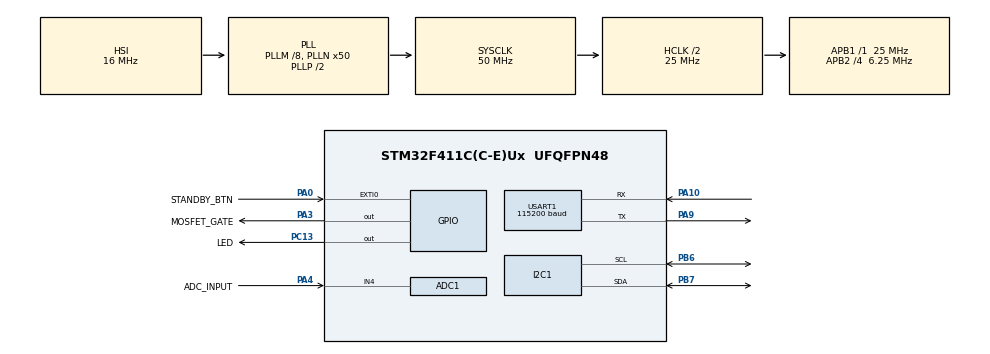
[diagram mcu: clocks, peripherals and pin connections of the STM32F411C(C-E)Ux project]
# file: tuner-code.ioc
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ADC1.Channel-0\#ChannelRegularConversion=ADC_CHANNEL_4
ADC1.ClockPrescaler=ADC_CLOCK_SYNC_PCLK_DIV8
ADC1.ContinuousConvMode=ENABLE
ADC1.DMAContinuousRequests=ENABLE
ADC1.NbrOfConversionFlag=1
ADC1.Rank-0\#ChannelRegularConversion=1
ADC1.SamplingTime-0\#ChannelRegularConversion=ADC_SAMPLETIME_84CYCLES
ADC1.master=1
Dma.ADC1.0.Direction=DMA_PERIPH_TO_MEMORY
Dma.ADC1.0.FIFOMode=DMA_FIFOMODE_DISABLE
Dma.ADC1.0.Instance=DMA2_Stream0
Dma.ADC1.0.MemDataAlignment=DMA_MDATAALIGN_HALFWORD
Dma.ADC1.0.MemInc=DMA_MINC_ENABLE
Dma.ADC1.0.Mode=DMA_NORMAL
Dma.ADC1.0.PeriphDataAlignment=DMA_PDATAALIGN_HALFWORD
Dma.ADC1.0.PeriphInc=DMA_PINC_DISABLE
Dma.ADC1.0.Priority=DMA_PRIORITY_HIGH
Dma.I2C1_TX.2.Direction=DMA_MEMORY_TO_PERIPH
Dma.I2C1_TX.2.FIFOMode=DMA_FIFOMODE_DISABLE
Dma.I2C1_TX.2.Instance=DMA1_Stream1
Dma.I2C1_TX.2.MemDataAlignment=DMA_MDATAALIGN_BYTE
Dma.I2C1_TX.2.MemInc=DMA_MINC_ENABLE
Dma.I2C1_TX.2.Mode=DMA_NORMAL
Dma.I2C1_TX.2.PeriphDataAlignment=DMA_PDATAALIGN_BYTE
Dma.I2C1_TX.2.PeriphInc=DMA_PINC_DISABLE
Dma.I2C1_TX.2.Priority=DMA_PRIORITY_MEDIUM
Dma.Request0=ADC1
Dma.Request1=USART1_TX
Dma.Request2=I2C1_TX
Dma.USART1_TX.1.Direction=DMA_MEMORY_TO_PERIPH
Dma.USART1_TX.1.FIFOMode=DMA_FIFOMODE_DISABLE
Dma.USART1_TX.1.Instance=DMA2_Stream7
Dma.USART1_TX.1.MemDataAlignment=DMA_MDATAALIGN_BYTE
Dma.USART1_TX.1.MemInc=DMA_MINC_ENABLE
Dma.USART1_TX.1.Mode=DMA_NORMAL
Dma.USART1_TX.1.PeriphDataAlignment=DMA_PDATAALIGN_BYTE
Dma.USART1_TX.1.PeriphInc=DMA_PINC_DISABLE
Dma.USART1_TX.1.Priority=DMA_PRIORITY_LOW
I2C1.I2C_Mode=I2C_Fast
Mcu.Family=STM32F4
Mcu.Name=STM32F411C(C-E)Ux
Mcu.Package=UFQFPN48
NVIC.DMA1_Stream1_IRQn=true\:0\:0\:false\:false\:true\:false\:true\:true
NVIC.DMA2_Stream0_IRQn=true\:0\:0\:false\:false\:true\:false\:true\:true
NVIC.DMA2_Stream7_IRQn=true\:0\:0\:false\:false\:true\:false\:true\:true
NVIC.EXTI0_IRQn=true\:0\:0\:false\:false\:true\:true\:true\:true
NVIC.I2C1_EV_IRQn=true\:0\:0\:false\:false\:true\:true\:true\:true
NVIC.PriorityGroup=NVIC_PRIORITYGROUP_4
NVIC.USART1_IRQn=true\:0\:0\:false\:false\:true\:true\:true\:true
PA0-WKUP.GPIO_Label=STANDBY_BTN
PA0-WKUP.Signal=GPXTI0
PA10.Mode=Asynchronous
PA10.Signal=USART1_RX
PA13.Mode=Serial_Wire
PA13.Signal=SYS_JTMS-SWDIO
PA14.Mode=Serial_Wire
PA14.Signal=SYS_JTCK-SWCLK
PA3.GPIO_Label=MOSFET_GATE
PA3.Signal=GPIO_Output
PA4.GPIO_Label=ADC_INPUT
PA4.Signal=ADCx_IN4
PA9.Mode=Asynchronous
PA9.Signal=USART1_TX
PB6.Mode=I2C
PB6.Signal=I2C1_SCL
PB7.Mode=I2C
PB7.Signal=I2C1_SDA
PC13-ANTI_TAMP.GPIO_Label=LED
PC13-ANTI_TAMP.GPIO_ModeDefaultOutputPP=GPIO_MODE_OUTPUT_PP
PC13-ANTI_TAMP.GPIO_PuPd=GPIO_NOPULL
PC13-ANTI_TAMP.PinState=GPIO_PIN_SET
PC13-ANTI_TAMP.Signal=GPIO_Output
ProjectManager.HeapSize=0x200
ProjectManager.StackSize=0x400
ProjectManager.TargetToolchain=CMake
RCC.48MHZClocksFreq_Value=25000000
RCC.AHBCLKDivider=RCC_SYSCLK_DIV2
RCC.AHBFreq_Value=25000000
RCC.APB1Freq_Value=25000000
RCC.APB1TimFreq_Value=25000000
RCC.APB2CLKDivider=RCC_HCLK_DIV4
RCC.APB2Freq_Value=6250000
RCC.APB2TimFreq_Value=12500000
RCC.CortexFreq_Value=25000000
RCC.HCLKFreq_Value=25000000
RCC.HSE_VALUE=25000000
RCC.HSI_VALUE=16000000
RCC.LSE_VALUE=32768
RCC.PLLM=8
RCC.PLLN=50
RCC.SYSCLKFreq_VALUE=50000000
RCC.SYSCLKSource=RCC_SYSCLKSOURCE_PLLCLK
RCC.VCOOutputFreq_Value=100000000
SH.ADCx_IN4.0=ADC1_IN4,IN4
STMicroelectronics.X-CUBE-ALGOBUILD.1.4.0.LibraryCcDSPOoLibraryJjDSPOoLibrary=true
USART1.BaudRate=115200
USART1.Mode=MODE_TX_RX
USART1.VirtualMode=VM_ASYNC
VP_STMicroelectronics.X-CUBE-ALGOBUILD_VS_DSPOoLibraryJjLibrary_1.4.0_1.4.0.Mode=DSPOoLibraryJjLibrary
board=custom

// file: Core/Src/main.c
/* USER CODE BEGIN Header */
/**
  ******************************************************************************
  * @file           : main.c
  * @brief          : Main program body
  ******************************************************************************
  * @attention
  *
  * Copyright (c) 2025 STMicroelectronics.
  * All rights reserved.
  *
  * This software is licensed under terms that can be found in the LICENSE file
  * in the root directory of this software component.
  * If no LICENSE file comes with this software, it is provided AS-IS.
  *
  ******************************************************************************
  */
/* USER CODE END Header */
#include "main.h"

ADC_HandleTypeDef hadc1;
DMA_HandleTypeDef hdma_adc1;

I2C_HandleTypeDef hi2c1;
DMA_HandleTypeDef hdma_i2c1_tx;

UART_HandleTypeDef huart1;
DMA_HandleTypeDef hdma_usart1_tx;

void SystemClock_Config(void);
static void MX_GPIO_Init(void);
static void MX_DMA_Init(void);
static void MX_ADC1_Init(void);
static void MX_I2C1_Init(void);
static void MX_USART1_UART_Init(void);
/* USER CODE BEGIN PFP */
__inline void SystemClockConfig(void)
{
    SystemClock_Config();
}

__inline void MxGpioInit(void)
{
    MX_GPIO_Init();
}

__inline void MxAdcInit(void)
{
    MX_ADC1_Init();
}

__inline void MxDmaInit(void)
{
    MX_DMA_Init();
}

__inline void MxUartInit(void)
{
    MX_USART1_UART_Init();
}

__inline void MxI2cInit(void)
{
  MX_I2C1_Init();
}
/* USER CODE END PFP */

void SystemClock_Config(void)
{
  RCC_OscInitTypeDef RCC_OscInitStruct = {0};
  RCC_ClkInitTypeDef RCC_ClkInitStruct = {0};

  /** Configure the main internal regulator output voltage
  */
  __HAL_RCC_PWR_CLK_ENABLE();
  __HAL_PWR_VOLTAGESCALING_CONFIG(PWR_REGULATOR_VOLTAGE_SCALE1);

  /** Initializes the RCC Oscillators according to the specified parameters
  * in the RCC_OscInitTypeDef structure.
  */
  RCC_OscInitStruct.OscillatorType = RCC_OSCILLATORTYPE_HSI;
  RCC_OscInitStruct.HSIState = RCC_HSI_ON;
  RCC_OscInitStruct.HSICalibrationValue = RCC_HSICALIBRATION_DEFAULT;
  RCC_OscInitStruct.PLL.PLLState = RCC_PLL_ON;
  RCC_OscInitStruct.PLL.PLLSource = RCC_PLLSOURCE_HSI;
  RCC_OscInitStruct.PLL.PLLM = 8;
  RCC_OscInitStruct.PLL.PLLN = 50;
  RCC_OscInitStruct.PLL.PLLP = RCC_PLLP_DIV2;
  RCC_OscInitStruct.PLL.PLLQ = 4;
  if (HAL_RCC_OscConfig(&RCC_OscInitStruct) != HAL_OK)
  {
    Error_Handler();
  }

  /** Initializes the CPU, AHB and APB buses clocks
  */
  RCC_ClkInitStruct.ClockType = RCC_CLOCKTYPE_HCLK|RCC_CLOCKTYPE_SYSCLK
                              |RCC_CLOCKTYPE_PCLK1|RCC_CLOCKTYPE_PCLK2;
  RCC_ClkInitStruct.SYSCLKSource = RCC_SYSCLKSOURCE_PLLCLK;
  RCC_ClkInitStruct.AHBCLKDivider = RCC_SYSCLK_DIV2;
  RCC_ClkInitStruct.APB1CLKDivider = RCC_HCLK_DIV1;
  RCC_ClkInitStruct.APB2CLKDivider = RCC_HCLK_DIV4;

  if (HAL_RCC_ClockConfig(&RCC_ClkInitStruct, FLASH_LATENCY_0) != HAL_OK)
  {
    Error_Handler();
  }
}

static void MX_ADC1_Init(void)
{

  ADC_ChannelConfTypeDef sConfig = {0};

  /** Configure the global features of the ADC (Clock, Resolution, Data Alignment and number of conversion)
  */
  hadc1.Instance = ADC1;
  hadc1.Init.ClockPrescaler = ADC_CLOCK_SYNC_PCLK_DIV8;
  hadc1.Init.Resolution = ADC_RESOLUTION_12B;
  hadc1.Init.ScanConvMode = DISABLE;
  hadc1.Init.ContinuousConvMode = ENABLE;
  hadc1.Init.DiscontinuousConvMode = DISABLE;
  hadc1.Init.ExternalTrigConvEdge = ADC_EXTERNALTRIGCONVEDGE_NONE;
  hadc1.Init.ExternalTrigConv = ADC_SOFTWARE_START;
  hadc1.Init.DataAlign = ADC_DATAALIGN_RIGHT;
  hadc1.Init.NbrOfConversion = 1;
  hadc1.Init.DMAContinuousRequests = ENABLE;
  hadc1.Init.EOCSelection = ADC_EOC_SINGLE_CONV;
  if (HAL_ADC_Init(&hadc1) != HAL_OK)
  {
    Error_Handler();
  }

  /** Configure for the selected ADC regular channel its corresponding rank in the sequencer and its sample time.
  */
  sConfig.Channel = ADC_CHANNEL_4;
  sConfig.Rank = 1;
  sConfig.SamplingTime = ADC_SAMPLETIME_84CYCLES;
  if (HAL_ADC_ConfigChannel(&hadc1, &sConfig) != HAL_OK)
  {
    Error_Handler();
  }

}

static void MX_I2C1_Init(void)
{

  hi2c1.Instance = I2C1;
  hi2c1.Init.ClockSpeed = 400000;
  hi2c1.Init.DutyCycle = I2C_DUTYCYCLE_2;
  hi2c1.Init.OwnAddress1 = 0;
  hi2c1.Init.AddressingMode = I2C_ADDRESSINGMODE_7BIT;
  hi2c1.Init.DualAddressMode = I2C_DUALADDRESS_DISABLE;
  hi2c1.Init.OwnAddress2 = 0;
  hi2c1.Init.GeneralCallMode = I2C_GENERALCALL_DISABLE;
  hi2c1.Init.NoStretchMode = I2C_NOSTRETCH_DISABLE;
  if (HAL_I2C_Init(&hi2c1) != HAL_OK)
  {
    Error_Handler();
  }

}

static void MX_USART1_UART_Init(void)
{

  huart1.Instance = USART1;
  huart1.Init.BaudRate = 115200;
  huart1.Init.WordLength = UART_WORDLENGTH_8B;
  huart1.Init.StopBits = UART_STOPBITS_1;
  huart1.Init.Parity = UART_PARITY_NONE;
  huart1.Init.Mode = UART_MODE_TX_RX;
  huart1.Init.HwFlowCtl = UART_HWCONTROL_NONE;
  huart1.Init.OverSampling = UART_OVERSAMPLING_16;
  if (HAL_UART_Init(&huart1) != HAL_OK)
  {
    Error_Handler();
  }

}

static void MX_DMA_Init(void)
{

  /* DMA controller clock enable */
  __HAL_RCC_DMA2_CLK_ENABLE();
  __HAL_RCC_DMA1_CLK_ENABLE();

  /* DMA interrupt init */
  /* DMA1_Stream1_IRQn interrupt configuration */
  HAL_NVIC_SetPriority(DMA1_Stream1_IRQn, 0, 0);
  HAL_NVIC_EnableIRQ(DMA1_Stream1_IRQn);
  /* DMA2_Stream0_IRQn interrupt configuration */
  HAL_NVIC_SetPriority(DMA2_Stream0_IRQn, 0, 0);
  HAL_NVIC_EnableIRQ(DMA2_Stream0_IRQn);
  /* DMA2_Stream7_IRQn interrupt configuration */
  HAL_NVIC_SetPriority(DMA2_Stream7_IRQn, 0, 0);
  HAL_NVIC_EnableIRQ(DMA2_Stream7_IRQn);

}

static void MX_GPIO_Init(void)
{
  GPIO_InitTypeDef GPIO_InitStruct = {0};

  /* GPIO Ports Clock Enable */
  __HAL_RCC_GPIOC_CLK_ENABLE();
  __HAL_RCC_GPIOA_CLK_ENABLE();
  __HAL_RCC_GPIOB_CLK_ENABLE();

  /*Configure GPIO pin Output Level */
  HAL_GPIO_WritePin(LED_GPIO_Port, LED_Pin, GPIO_PIN_SET);

  /*Configure GPIO pin Output Level */
  HAL_GPIO_WritePin(MOSFET_GATE_GPIO_Port, MOSFET_GATE_Pin, GPIO_PIN_RESET);

  /*Configure GPIO pin : LED_Pin */
  GPIO_InitStruct.Pin = LED_Pin;
  GPIO_InitStruct.Mode = GPIO_MODE_OUTPUT_PP;
  GPIO_InitStruct.Pull = GPIO_NOPULL;
  GPIO_InitStruct.Speed = GPIO_SPEED_FREQ_LOW;
  HAL_GPIO_Init(LED_GPIO_Port, &GPIO_InitStruct);

  /*Configure GPIO pin : STANDBY_BTN_Pin */
  GPIO_InitStruct.Pin = STANDBY_BTN_Pin;
  GPIO_InitStruct.Mode = GPIO_MODE_IT_RISING;
  GPIO_InitStruct.Pull = GPIO_NOPULL;
  HAL_GPIO_Init(STANDBY_BTN_GPIO_Port, &GPIO_InitStruct);

  /*Configure GPIO pin : MOSFET_GATE_Pin */
  GPIO_InitStruct.Pin = MOSFET_GATE_Pin;
  GPIO_InitStruct.Mode = GPIO_MODE_OUTPUT_PP;
  GPIO_InitStruct.Pull = GPIO_NOPULL;
  GPIO_InitStruct.Speed = GPIO_SPEED_FREQ_LOW;
  HAL_GPIO_Init(MOSFET_GATE_GPIO_Port, &GPIO_InitStruct);

  /* EXTI interrupt init*/
  HAL_NVIC_SetPriority(EXTI0_IRQn, 0, 0);
  HAL_NVIC_EnableIRQ(EXTI0_IRQn);

}

void Error_Handler(void)
{
    __disable_irq();
    while (1)
    {
    }
}
